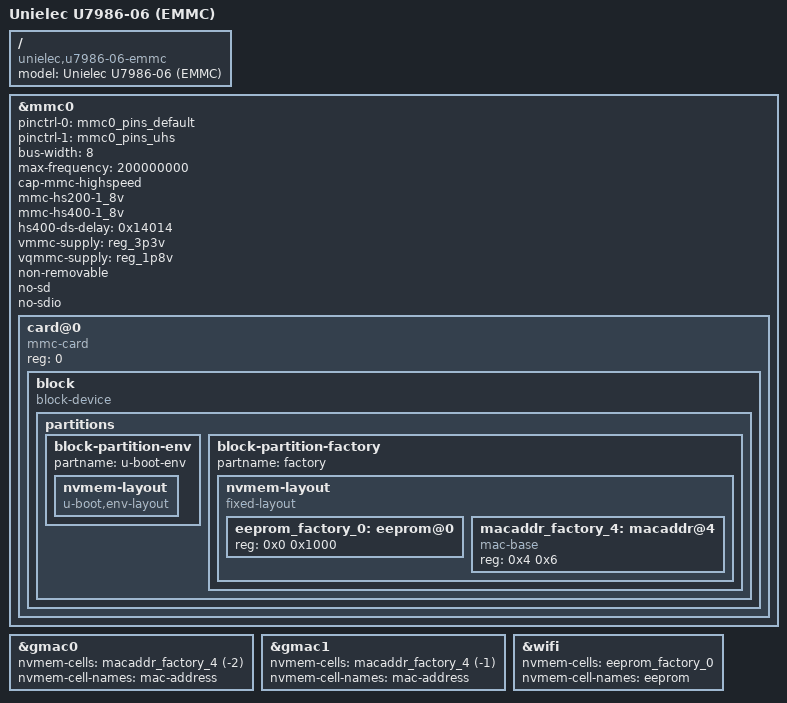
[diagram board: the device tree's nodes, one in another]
// SPDX-License-Identifier: GPL-2.0-or-later OR MIT
/*
 * Copyright (C) 2023 Allen Zhao <allenzhao@unielecinc.com>
 */

/dts-v1/;
#include "mt7986a-unielec-u7986-06.dtsi"

/ {
	model = "Unielec U7986-06 (EMMC)";
	compatible = "unielec,u7986-06-emmc", "mediatek,mt7986";
};

&mmc0 {
	pinctrl-names = "default", "state_uhs";
	pinctrl-0 = <&mmc0_pins_default>;
	pinctrl-1 = <&mmc0_pins_uhs>;
	bus-width = <8>;
	max-frequency = <200000000>;
	cap-mmc-highspeed;
	mmc-hs200-1_8v;
	mmc-hs400-1_8v;
	hs400-ds-delay = <0x14014>;
	vmmc-supply = <&reg_3p3v>;
	vqmmc-supply = <&reg_1p8v>;
	non-removable;
	no-sd;
	no-sdio;
	status = "okay";

	card@0 {
		compatible = "mmc-card";
		reg = <0>;

		block {
			compatible = "block-device";
			partitions {
				block-partition-env {
					partname = "u-boot-env";

					nvmem-layout {
						compatible = "u-boot,env-layout";
					};
				};

				block-partition-factory {
					partname = "factory";

					nvmem-layout {
						compatible = "fixed-layout";
						#address-cells = <1>;
						#size-cells = <1>;

						eeprom_factory_0: eeprom@0 {
							reg = <0x0 0x1000>;
						};

						macaddr_factory_4: macaddr@4 {
							compatible = "mac-base";
							reg = <0x4 0x6>;
							#nvmem-cell-cells = <1>;
						};
					};
				};
			};
		};
	};
};

&gmac0 {
	nvmem-cells = <&macaddr_factory_4 (-2)>;
	nvmem-cell-names = "mac-address";
};

&gmac1 {
	nvmem-cells = <&macaddr_factory_4 (-1)>;
	nvmem-cell-names = "mac-address";
};

&wifi {
	nvmem-cells = <&eeprom_factory_0>;
	nvmem-cell-names = "eeprom";
	status = "okay";
};
